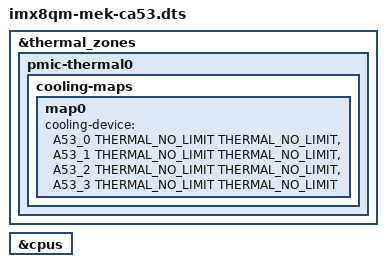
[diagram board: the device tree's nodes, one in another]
// SPDX-License-Identifier: GPL-2.0+
/*
 * Copyright 2019 NXP
 */

/dts-v1/;

#include "imx8qm-mek.dts"

&thermal_zones {
	/delete-node/	cpu1-thermal;

	pmic-thermal0 {
		cooling-maps {
			map0 {
				cooling-device =
				<&A53_0 THERMAL_NO_LIMIT THERMAL_NO_LIMIT>,
				<&A53_1 THERMAL_NO_LIMIT THERMAL_NO_LIMIT>,
				<&A53_2 THERMAL_NO_LIMIT THERMAL_NO_LIMIT>,
				<&A53_3 THERMAL_NO_LIMIT THERMAL_NO_LIMIT>;
			};
		};
	};
};

&cpus {
	/delete-node/ cpu-map;
	/delete-node/ cpu@100;
	/delete-node/ cpu@101;
};
